AUTOSAR XML (schema 4-3-0)
package /ComponentTypes
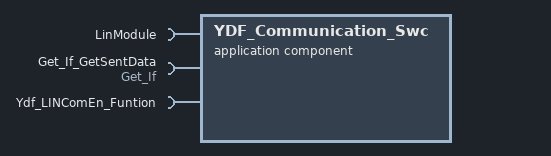
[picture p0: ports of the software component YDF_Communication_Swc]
  application sw component type YDF_Communication_Swc
    require port LinModule: required-interface=LinModule
      required-com-specs:
        LinA_Master_Send
        LinB_Master_Send
        LinC_Master_Send
        LinA_Slave_Response
        LinB_Slave_Response
        LinC_Slave_Response
        LinARec_GetResult
        LinBRec_GetResult
        LinCRec_GetResult
        LinDRec_GetResult
        LinD_Slave_Response
        LinD_Master_Send
    require port Get_If_GetSentData: required-interface=Get_If
      required-com-specs:
        Get_Ad_Result
        Get_io_inResult
        Get_BTS_OutResult
        Get_CAN_ActiveInf
        Icu_17_GtmCcu6_PWMIN_CH{1..4}
        Icu_17_GtmCcu6_PWMIN_PWMSCB1
        Icu_17_GtmCcu6_PWMIN_PWMSCB2
        Icu_17_GtmCcu6_PWMIN_LAMPSCB1
        Icu_17_GtmCcu6_PWMIN_LAMPSCB2
        Get_Bottom_Ver
        Get_SentData
        Get_Level_OutResult
        Get_PwmOrLevel_OutResult
        Get_Motor_OutResult
    require port Ydf_LINComEn_Funtion: required-com-specs=[LINB_OUT_Enable, LINC_OUT_Enable, LIND_OUT_Enable], required-interface=Ydf_LINComEn_Funtion
    behavior YDF_Communication_Swc_InternalBehavior
      4 x timing event, all with period=0.01:
        TMT_YDF_LinManagement: start-on-event=YDF_LinManagement
        TMT_YDF_SentManagement: start-on-event=YDF_SentManagement
        TMT_YDF_CANManagement: start-on-event=YDF_CANManagement
        TMT_YDF_EthManagement: start-on-event=YDF_EthManagement
      4 x runnable:
        YDF_EthManagement
        YDF_LinManagement
          async call AC_Ydf_LINComEn_Funtion_LINA_OUT_Enable: operation=Ydf_LINComEn_Funtion.LIND_OUT_Enable
          async call AC_Ydf_LINComEn_Funtion_LINB_OUT_Enable: operation=Ydf_LINComEn_Funtion.LINB_OUT_Enable
          async call AC_Ydf_LINComEn_Funtion_LINC_OUT_Enable: operation=Ydf_LINComEn_Funtion.LINC_OUT_Enable
          12 x sync call:
            SC_LinModule_LinARec_GetResult: operation=LinModule.LinARec_GetResult
            SC_LinModule_LinA_Master_Send: operation=LinModule.LinA_Master_Send
            SC_LinModule_LinA_Slave_Response: operation=LinModule.LinA_Slave_Response
            SC_LinModule_LinBRec_GetResult: operation=LinModule.LinBRec_GetResult
            SC_LinModule_LinB_Master_Send: operation=LinModule.LinB_Master_Send
            SC_LinModule_LinB_Slave_Response: operation=LinModule.LinB_Slave_Response
            SC_LinModule_LinCRec_GetResult: operation=LinModule.LinCRec_GetResult
            SC_LinModule_LinC_Master_Send: operation=LinModule.LinC_Master_Send
            SC_LinModule_LinC_Slave_Response: operation=LinModule.LinC_Slave_Response
            SC_LinModule_LinDRec_GetResult: operation=LinModule.LinDRec_GetResult
            SC_LinModule_LinD_Master_Send: operation=LinModule.LinD_Master_Send
            SC_LinModule_LinD_Slave_Response: operation=LinModule.LinD_Slave_Response
        YDF_SentManagement
        YDF_CANManagement
          10 x sync call:
            SC_Get_If_GetSentData_Get_SentData: operation=Get_If_GetSentData.Get_SentData
            SC_LinModule_LinARec_GetResult: operation=LinModule.LinARec_GetResult
            SC_LinModule_LinA_Master_Send: operation=LinModule.LinA_Master_Send
            SC_LinModule_LinA_Slave_Response: operation=LinModule.LinA_Slave_Response
            SC_LinModule_LinBRec_GetResult: operation=LinModule.LinBRec_GetResult
            SC_LinModule_LinB_Master_Send: operation=LinModule.LinB_Master_Send
            SC_LinModule_LinB_Slave_Response: operation=LinModule.LinB_Slave_Response
            SC_LinModule_LinCRec_GetResult: operation=LinModule.LinCRec_GetResult
            SC_LinModule_LinC_Master_Send: operation=LinModule.LinC_Master_Send
            SC_LinModule_LinC_Slave_Response: operation=LinModule.LinC_Slave_Response
  swc implementation YDF_Communication_Swc_Implementation: behavior=YDF_Communication_Swc_InternalBehavior
